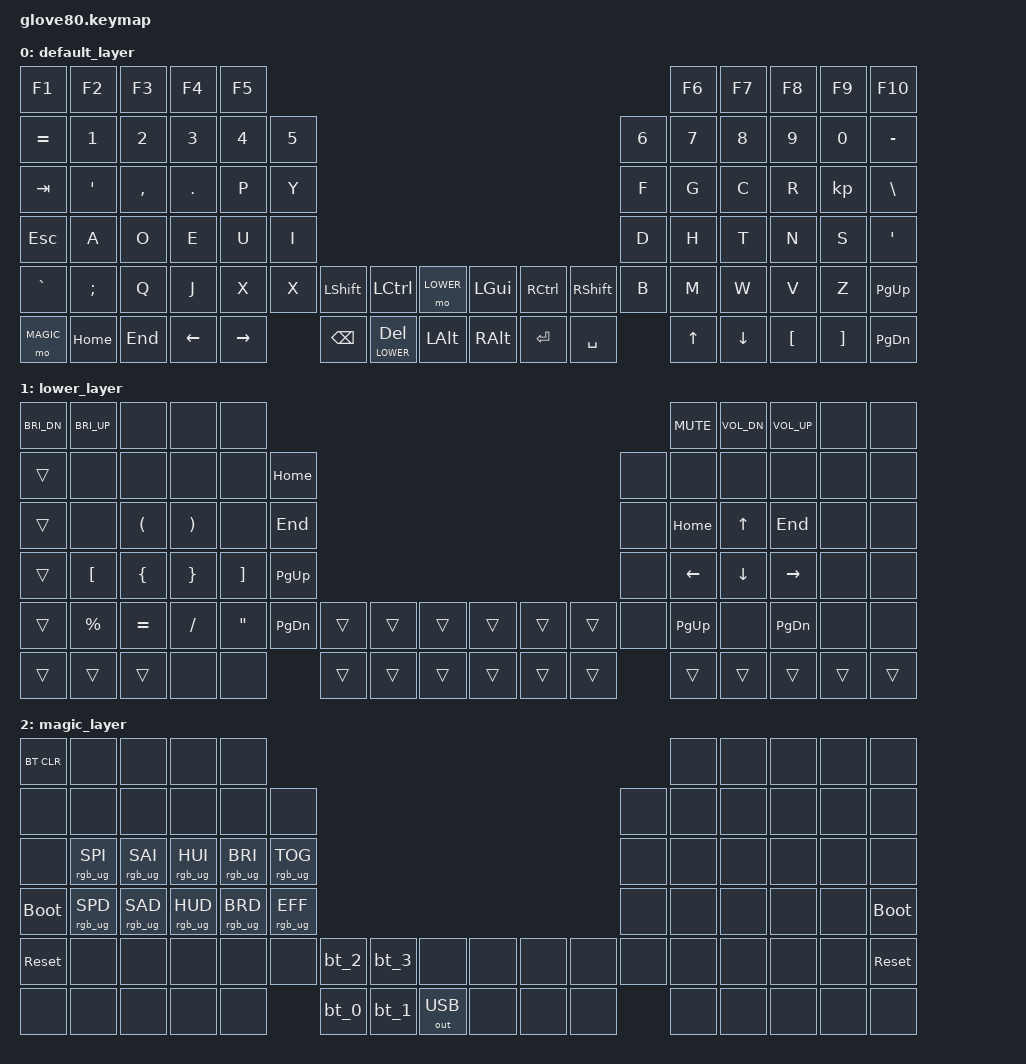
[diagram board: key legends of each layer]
/*
 * Copyright (c) 2020 The ZMK Contributors
 *
 * SPDX-License-Identifier: MIT
 */

#include <behaviors.dtsi>
#include <dt-bindings/zmk/keys.h>
#include <dt-bindings/zmk/bt.h>
#include <dt-bindings/zmk/ext_power.h>
#include <dt-bindings/zmk/outputs.h>
#include <dt-bindings/zmk/rgb.h>

// layers
#define DEFAULT 0
#define LOWER 1
#define MOUSE 2
#define MAGIC 3

/ {
    behaviors {
        // For the "layer" key, it'd nice to be able to use it as either a shift or a toggle.
        // Configure it as a tap dance, so the first tap (or hold) is a &mo and the second tap is a &to
        layer_td: tap_dance_0 {
            compatible = "zmk,behavior-tap-dance";
            #binding-cells = <0>;
            tapping-term-ms = <200>;
            bindings = <&mo LOWER>, <&to LOWER>;
        };
    };

    macros {
        bt_0: bt_profile_macro_0 {
            compatible = "zmk,behavior-macro";
            #binding-cells = <0>;
            bindings
                = <&out OUT_BLE>,
                  <&bt BT_SEL 0>;
        };

        bt_1: bt_profile_macro_1 {
            compatible = "zmk,behavior-macro";
            #binding-cells = <0>;
            bindings
                = <&out OUT_BLE>,
                  <&bt BT_SEL 1>;
        };

        bt_2: bt_profile_macro_2 {
            compatible = "zmk,behavior-macro";
            #binding-cells = <0>;
            bindings
                = <&out OUT_BLE>,
                  <&bt BT_SEL 2>;
        };

        bt_3: bt_profile_macro_3 {
            compatible = "zmk,behavior-macro";
            #binding-cells = <0>;
            bindings
                = <&out OUT_BLE>,
                  <&bt BT_SEL 3>;
        };
    };

    keymap {
        compatible = "zmk,keymap";

        default_layer {
            // ---------------------------------------------------------------------------------------------------------------------------------
            // |  F1   |  F2 |  F3 |  F4  |  F5  |                                                               |  F6   |  F7   |  F8  |   F9  |  F10 |
            // |  =    |  1  |  2  |  3   |  4   |  5   |                                                 |  6   |   7   |   8   |  9   |   0   |   -  |
            // |  TAB  |  '  |  ,  |  .   |  P   |  Y   |                                                 |  F   |   G   |   C   |  R   |   L   |   \  |
            // |  ESC  |  A  |  O  |  E   |  U   |  I   |                                                 |  D   |   H   |   T   |  N   |   S   |   -  |
            // |   `   |  ;  |  Q  |  J   |  K   |  X   | LSHFT | LCTRL | LOWER | | LGUI  | RCTRL | RSHFT |  B   |   M   |   W   |  V   |   Z   | PGUP |
            // | MAGIC | HOME| END | LEFT | RIGHT|      | BSPC  | DEL   | LALT  | | RALT  | RET   | SPACE |      |  UP   | DOWN  |  [   |   ]   | PGDN |
        bindings = <
            &kp F1         &kp F2   &kp F3      &kp F4      &kp F5                                                                                         &kp F6  &kp F7      &kp F8      &kp F9      &kp F10
            &kp EQUAL      &kp N1   &kp N2      &kp N3      &kp N4      &kp N5                                                                     &kp N6  &kp N7  &kp N8      &kp N9      &kp N0      &kp MINUS
            &kp TAB        &kp SQT  &kp COMMA   &kp DOT     &kp P       &kp Y                                                                      &kp F   &kp G   &kp C       &kp R       &kp         &kp BSLH
            &kp ESC        &kp A    &kp O       &kp E       &kp U       &kp I                                                                      &kp D   &kp H   &kp T       &kp N       &kp S       &kp SQT
            &kp GRAVE      &kp SEMI &kp Q       &kp J       &kp X       &kp X   &kp LSHFT   &kp LCTRL      &mo LOWER &kp LGUI  &kp RCTRL &kp RSHFT &kp B   &kp M   &kp W       &kp V       &kp Z       &kp PG_UP
            &mo MAGIC      &kp HOME &kp END     &kp LEFT    &kp RIGHT           &kp BSPC    &lt LOWER DEL  &kp LALT  &kp RALT  &kp RET   &kp SPACE         &kp UP  &kp DOWN    &kp LBKT    &kp RBKT    &kp PG_DN
            >;
        };

        lower_layer {
            bindings = <
            &kp C_BRI_DN      &kp C_BRI_UP        &none           &none           &none                                                                                                           &kp C_MUTE   &kp C_VOL_DN &kp C_VOL_UP  &none           &none
            &trans            &none               &none           &none           &none           &kp HOME                                                                              &none     &none        &none        &none         &none           &none
            &trans            &none               &kp LPAR        &kp RPAR        &none           &kp END                                                                               &none     &kp HOME     &kp UP       &kp END       &none           &none
            &trans            &kp LBKT            &kp LBRC        &kp RBRC        &kp RBKT        &kp PG_UP                                                                             &none     &kp LEFT     &kp DOWN     &kp RIGHT     &none           &none
            &trans            &kp PRCNT           &kp EQUAL       &kp FSLH        &kp DQT         &kp PG_DN       &trans      &trans     &trans     &trans      &trans      &trans      &none     &kp PG_UP    &none        &kp PG_DN     &none           &none
            &trans            &trans              &trans          &none           &none                           &trans      &trans     &trans     &trans      &trans      &trans                &trans       &trans       &trans        &trans          &trans
            >;
        };

        magic_layer {
            bindings = <
            &bt BT_CLR        &none               &none           &none           &none                                                                                                           &none      &none      &none      &none      &none
            &none             &none               &none           &none           &none           &none                                                                                &none      &none      &none      &none      &none      &none
            &none             &rgb_ug RGB_SPI     &rgb_ug RGB_SAI &rgb_ug RGB_HUI &rgb_ug RGB_BRI &rgb_ug RGB_TOG                                                                      &none      &none      &none      &none      &none      &none
            &bootloader       &rgb_ug RGB_SPD     &rgb_ug RGB_SAD &rgb_ug RGB_HUD &rgb_ug RGB_BRD &rgb_ug RGB_EFF                                                                      &none      &none      &none      &none      &none      &bootloader
            &sys_reset        &none               &none           &none           &none           &none           &bt_2     &bt_3     &none            &none     &none     &none       &none      &none      &none      &none      &none      &sys_reset
            &none             &none               &none           &none           &none                           &bt_0     &bt_1     &out OUT_USB     &none     &none     &none                  &none      &none      &none      &none      &none
            >;
        };
    };
};
